# GD32E501 register map
File version: 1.0
CPU: CM33 r0p4, little endian, MPU, FPU, 4 interrupt priority bits
Registers are 32-bit, read-write, reset 0x0 unless marked. A register's access mark holds for its fields unless they carry their own. Offsets are from the block's base; [hi:lo] are bit positions; {n}, {i} and the like mark numbered series.

## FWDGT — free watchdog timer
Base 0x40003000
0x00 CTL wo — Control register
  [15:0] CMD — Key value
0x04 PSC — Prescaler register
  [2:0] PSC — Prescaler divider
0x08 RLD reset 0xFFF — Reload register
  [11:0] RLD — Watchdog counter reload value
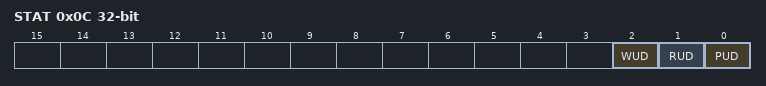
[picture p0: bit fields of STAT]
0x0C STAT ro — Status register
  [2] WUD — Watchdog counter window value update
  [1] RUD — Watchdog counter reload value update
  [0] PUD — Watchdog prescaler value update
0x10 WND reset 0xFFF — Window register
  [11:0] WND — Watchdog counter window value

## GPIOA — General-purpose I/Os
Base 0x48000000
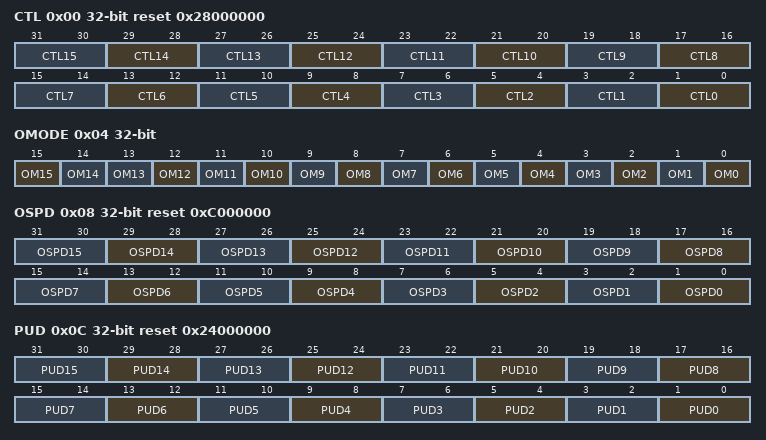
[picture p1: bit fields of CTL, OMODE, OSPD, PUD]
0x00 CTL reset 0x28000000 — GPIO port control register
  [2n+1:2n] CTL{n} (n=0..15) — Pin {n} configuration bits
0x04 OMODE — GPIO port output type register
  [15] OM15 — Pin 15 output mode bit
  [14] OM14 — Pin 15 output mode bit
  [n] OM{n} (n=0..13) — Pin {n} output mode bit
0x08 OSPD reset 0xC000000 — GPIO port output speed register
  [2n+1:2n] OSPD{n} (n=0..15) — Pin {n} output max speed bits
0x0C PUD reset 0x24000000 — GPIO port pull-up/pull-down register
  [2n+1:2n] PUD{n} (n=0..15) — Pin {n} pull-up or pull-down bits
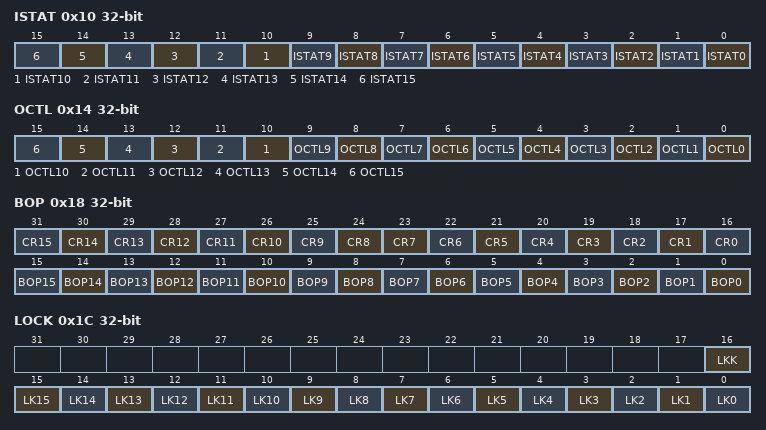
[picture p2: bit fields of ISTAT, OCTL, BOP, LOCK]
0x10 ISTAT ro — GPIO input status register
  [n] ISTAT{n} (n=0..15) — Port input status
0x14 OCTL — GPIO port output control register
  [n] OCTL{n} (n=0..15) — Port output data (y = 0..15)
0x18 BOP wo — GPIO port bit operate register
  [n+16] CR{n} (n=8..15) — Pin {n} reset bit
  [23] CR7 — Pin 7 reset bit)
  [n+16] CR{n} (n=2..6) — Pin {n} reset bit
  [17] CR1 — Pin 2 reset bit
  [16] CR0 — Pin 0 reset bit
  [n] BOP{n} (n=0..15) — Pin {n} set bit
0x1C LOCK — GPIO port configuration lock register
  [16] LKK — Lock key
  [n] LK{n} (n=0..15) — Port A lock bit {n}
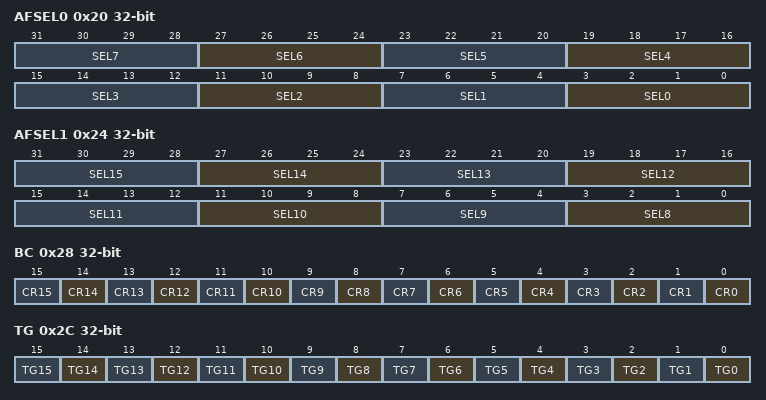
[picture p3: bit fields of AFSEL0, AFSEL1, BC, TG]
0x20 AFSEL0 — GPIO alternate function selected register 0
  [4n+3:4n] SEL{n} (n=0..7) — Pin {n} alternate function selected
0x24 AFSEL1 — GPIO alternate function seclected register 1
  [4n-29:4n-32] SEL{n} (n=8..15) — Pin {n} alternate function selected
0x28 BC wo — Port bit reset register
  [n] CR{n} (n=0..15) — Port cleat bit
0x2C TG wo — Port bit toggle register
  [n] TG{n} (n=0..15) — Port toggle bit

## GPIOB — General-purpose I/Os
Base 0x48000400
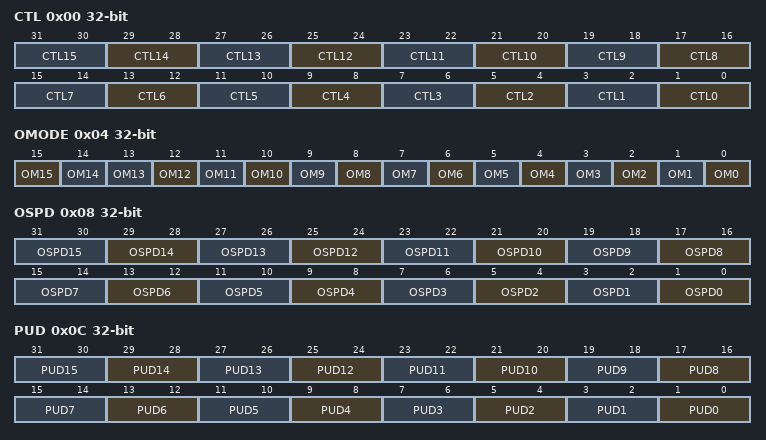
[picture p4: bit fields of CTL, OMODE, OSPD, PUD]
0x00 CTL — GPIO port control register
  [2n+1:2n] CTL{n} (n=0..15) — Pin {n} configuration bits
0x04 OMODE — GPIO port output type register
  [15] OM15 — Pin 15 output mode bit
  [14] OM14 — Pin 15 output mode bit
  [n] OM{n} (n=0..13) — Pin {n} output mode bit
0x08 OSPD — GPIO port output speed register
  [2n+1:2n] OSPD{n} (n=0..15) — Pin {n} output max speed bits
0x0C PUD — GPIO port pull-up/pull-down register
  [2n+1:2n] PUD{n} (n=0..15) — Pin {n} pull-up or pull-down bits
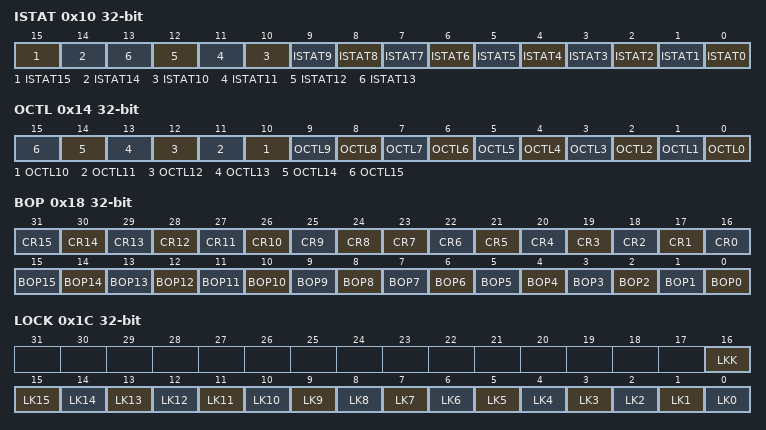
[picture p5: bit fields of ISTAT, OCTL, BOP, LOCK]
0x10 ISTAT ro — GPIO port input data register
  [15] ISTAT15 — Port input status
  [14] ISTAT14 — PPort input status
  [n] ISTAT{n} (n=0..13) — Port input status
0x14 OCTL — GPIO port output data register
  [n] OCTL{n} (n=0..15) — Port output data
0x18 BOP wo — GPIO port bit set/reset register
  [n+16] CR{n} (n=8..15) — Pin {n} reset bit
  [23] CR7 — Pin 7 reset bit)
  [n+16] CR{n} (n=2..6) — Pin {n} reset bit
  [17] CR1 — Pin 2 reset bit
  [16] CR0 — Pin 0 reset bit
  [n] BOP{n} (n=0..15) — Pin {n} set bit
0x1C LOCK — GPIO port configuration lock register
  [16] LKK — Lock key
  [n] LK{n} (n=0..15) — Port A lock bit {n}
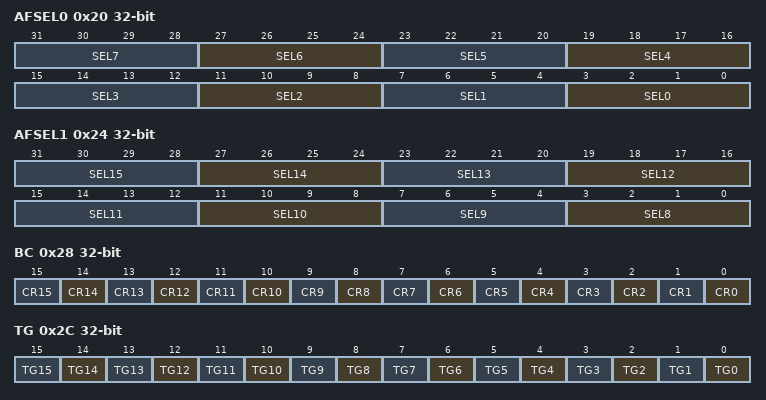
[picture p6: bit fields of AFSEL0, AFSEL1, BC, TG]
0x20 AFSEL0 — GPIO alternate function low register
  [4n+3:4n] SEL{n} (n=0..7) — Pin {n} alternate function selected
0x24 AFSEL1 — GPIO alternate function register 1
  [4n-29:4n-32] SEL{n} (n=8..15) — Pin {n} alternate function selected
0x28 BC wo — Port bit reset register
  [n] CR{n} (n=0..15) — Port cleat bit
0x2C TG wo — Port bit toggle register
  [n] TG{n} (n=0..15) — Port toggle bit

## GPIOC — General-purpose I/Os
Base 0x48000800
Registers as GPIOB, without LOCK.

## GPIOD — General-purpose I/Os
Base 0x48000C00
Registers as GPIOB, without LOCK.

## GPIOF — General-purpose I/Os
Base 0x48001400
Registers as GPIOB, without LOCK; these are added or differ:
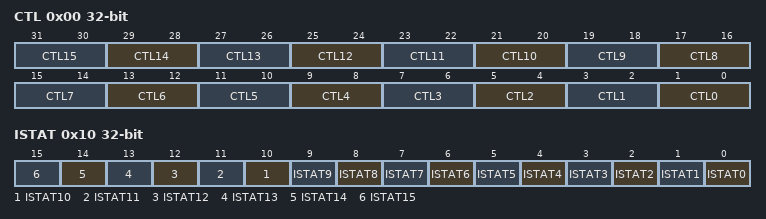
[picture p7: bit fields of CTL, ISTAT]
0x00 CTL — GPIOF port control register
  [2n+1:2n] CTL{n} (n=0..15) — Pin {n} configuration bits
0x10 ISTAT ro — GPIO port input data register
  [n] ISTAT{n} (n=0..15) — Port input data
